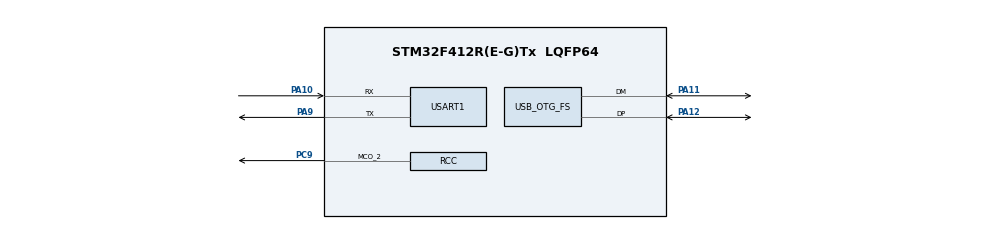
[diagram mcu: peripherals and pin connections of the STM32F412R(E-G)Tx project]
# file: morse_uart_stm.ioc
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Mcu.Family=STM32F4
Mcu.Name=STM32F412R(E-G)Tx
Mcu.Package=LQFP64
NVIC.OTG_FS_IRQn=true\:0\:0\:false\:false\:true\:false\:true\:true
NVIC.PriorityGroup=NVIC_PRIORITYGROUP_4
NVIC.USART1_IRQn=true\:0\:0\:false\:false\:true\:true\:true\:true
PA10.Mode=Asynchronous
PA10.Signal=USART1_RX
PA11.Mode=Device_Only
PA11.Signal=USB_OTG_FS_DM
PA12.Mode=Device_Only
PA12.Signal=USB_OTG_FS_DP
PA9.Mode=Asynchronous
PA9.Signal=USART1_TX
PC9.Mode=Clock-out-2
PC9.Signal=RCC_MCO_2
PH0\ -\ OSC_IN.Mode=HSE-External-Oscillator
PH0\ -\ OSC_IN.Signal=RCC_OSC_IN
PH1\ -\ OSC_OUT.Mode=HSE-External-Oscillator
PH1\ -\ OSC_OUT.Signal=RCC_OSC_OUT
ProjectManager.HeapSize=0x200
ProjectManager.StackSize=0x400
ProjectManager.TargetToolchain=CMake
RCC.CortexFreq_Value=16000000
RCC.HSE_VALUE=16000000
RCC.PLLM=8
RCC.PLLN=72
RCC.PLLQ=3
RCC.USBFreq_Value=48000000
RCC.VCOOutputFreq_Value=144000000
USART1.VirtualMode=VM_ASYNC
USB_DEVICE.CLASS_NAME_FS=CDC
USB_DEVICE.MANUFACTURER_STRING=schoeguu
USB_DEVICE.PID_CDC_FS=1
USB_DEVICE.PRODUCT_STRING_CDC_FS=iCEBrainstorm
USB_DEVICE.VID=1
USB_DEVICE.VirtualMode=Cdc
USB_DEVICE.VirtualModeFS=Cdc_FS
USB_OTG_FS.VirtualMode=Device_Only
VP_USB_DEVICE_VS_USB_DEVICE_CDC_FS.Mode=CDC_FS
board=custom

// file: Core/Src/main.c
/* USER CODE BEGIN Header */
/**
  ******************************************************************************
  * @file           : main.c
  * @brief          : Main program body
  ******************************************************************************
  * @attention
  *
  * Copyright (c) 2026 STMicroelectronics.
  * All rights reserved.
  *
  * This software is licensed under terms that can be found in the LICENSE file
  * in the root directory of this software component.
  * If no LICENSE file comes with this software, it is provided AS-IS.
  *
  ******************************************************************************
  */
/* USER CODE END Header */
#include "main.h"
#include "usart.h"
#include "usb_device.h"
#include "gpio.h"

/* USER CODE BEGIN Includes */
#include "usbd_cdc_if.h"

/* USER CODE END Includes */

/* USER CODE BEGIN PV */
uint8_t uart_rx_buf;

/* USER CODE END PV */

void SystemClock_Config(void);

/* USER CODE BEGIN 0 */

// uint8_t uart_rx_buf; // Buffer to store the recieved UART message in

/* USER CODE END 0 */

int main(void)
{

  /* MCU Configuration--------------------------------------------------------*/

  /* Reset of all peripherals, Initializes the Flash interface and the Systick. */
  HAL_Init();

  /* Configure the system clock */
  SystemClock_Config();

  /* Initialize all configured peripherals */
  MX_GPIO_Init();
  MX_USART1_UART_Init();
  MX_USB_DEVICE_Init();
  /* USER CODE BEGIN 2 */
  HAL_UART_Receive_IT(&huart1, &uart_rx_buf, 1); //set up the first reception

  /* USER CODE END 2 */

  /* Infinite loop */
  while (1)
  {

  }
}

void SystemClock_Config(void)
{
  RCC_OscInitTypeDef RCC_OscInitStruct = {0};
  RCC_ClkInitTypeDef RCC_ClkInitStruct = {0};

  /** Configure the main internal regulator output voltage
  */
  __HAL_RCC_PWR_CLK_ENABLE();
  __HAL_PWR_VOLTAGESCALING_CONFIG(PWR_REGULATOR_VOLTAGE_SCALE1);

  /** Initializes the RCC Oscillators according to the specified parameters
  * in the RCC_OscInitTypeDef structure.
  */
  RCC_OscInitStruct.OscillatorType = RCC_OSCILLATORTYPE_HSI|RCC_OSCILLATORTYPE_HSE;
  RCC_OscInitStruct.HSEState = RCC_HSE_ON;
  RCC_OscInitStruct.HSIState = RCC_HSI_ON;
  RCC_OscInitStruct.HSICalibrationValue = RCC_HSICALIBRATION_DEFAULT;
  RCC_OscInitStruct.PLL.PLLState = RCC_PLL_ON;
  RCC_OscInitStruct.PLL.PLLSource = RCC_PLLSOURCE_HSE;
  RCC_OscInitStruct.PLL.PLLM = 8;
  RCC_OscInitStruct.PLL.PLLN = 72;
  RCC_OscInitStruct.PLL.PLLP = RCC_PLLP_DIV2;
  RCC_OscInitStruct.PLL.PLLQ = 3;
  RCC_OscInitStruct.PLL.PLLR = 2;
  if (HAL_RCC_OscConfig(&RCC_OscInitStruct) != HAL_OK)
  {
    Error_Handler();
  }

  /** Initializes the CPU, AHB and APB buses clocks
  */
  RCC_ClkInitStruct.ClockType = RCC_CLOCKTYPE_HCLK|RCC_CLOCKTYPE_SYSCLK
                              |RCC_CLOCKTYPE_PCLK1|RCC_CLOCKTYPE_PCLK2;
  RCC_ClkInitStruct.SYSCLKSource = RCC_SYSCLKSOURCE_HSI;
  RCC_ClkInitStruct.AHBCLKDivider = RCC_SYSCLK_DIV1;
  RCC_ClkInitStruct.APB1CLKDivider = RCC_HCLK_DIV1;
  RCC_ClkInitStruct.APB2CLKDivider = RCC_HCLK_DIV1;

  if (HAL_RCC_ClockConfig(&RCC_ClkInitStruct, FLASH_LATENCY_0) != HAL_OK)
  {
    Error_Handler();
  }
  HAL_RCC_MCOConfig(RCC_MCO2, RCC_MCO2SOURCE_SYSCLK, RCC_MCODIV_1);
}

/* USER CODE BEGIN 4 */

void HAL_UART_RxCpltCallback(UART_HandleTypeDef *huart) {
  if (huart == &huart1){
     CDC_Transmit_FS(&uart_rx_buf, 1); //send recieved byte over usb
     HAL_UART_Receive_IT(&huart1, &uart_rx_buf, 1);
    }
}

/* USER CODE END 4 */

void Error_Handler(void)
{
  __disable_irq();
  while (1)
  {
  }
}
